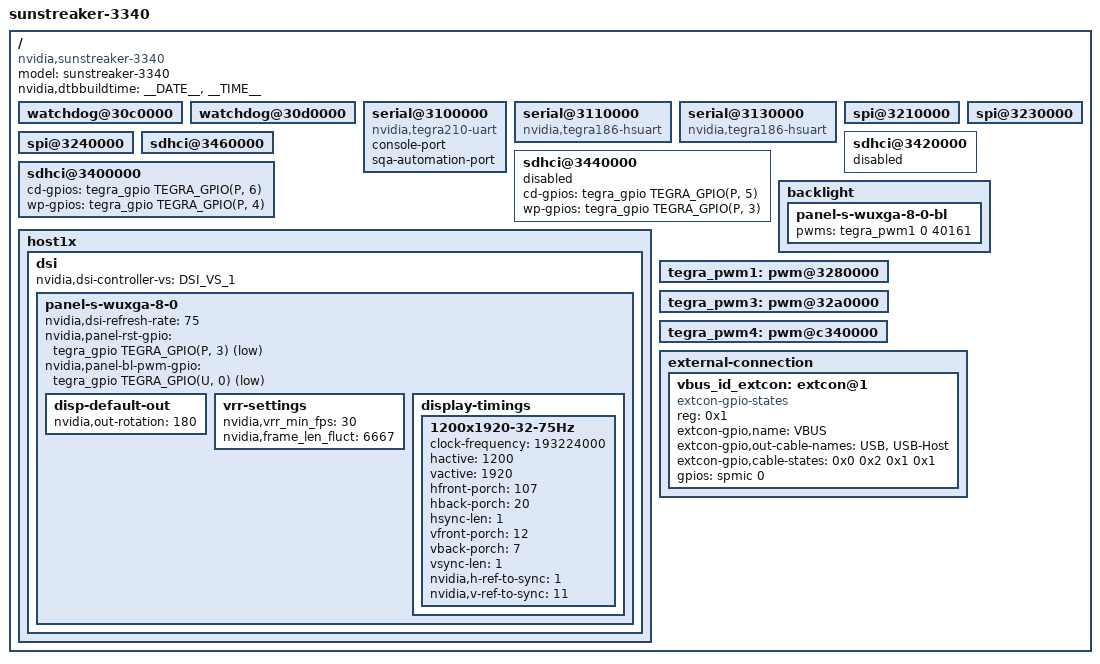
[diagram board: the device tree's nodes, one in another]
/*
 * tegra186-sunstreaker-common-e3340-0000-a00.dtsi: Sunstreaker common dtsi.
 *
 * Copyright (c) 2015, NVIDIA CORPORATION.  All rights reserved.
 *
 * This program is free software; you can redistribute it and/or modify
 * it under the terms of the GNU General Public License as published by
 * the Free Software Foundation; version 2 of the License.
 *
 * This program is distributed in the hope that it will be useful, but WITHOUT
 * ANY WARRANTY; without even the implied warranty of MERCHANTABILITY or
 * FITNESS FOR A PARTICULAR PURPOSE.  See the GNU General Public License for
 * more details.
 */

#include <dt-bindings/types.h>
#include <dt-bindings/gpio/tegra-gpio.h>
/dts-v1/;

/memreserve/ 0x80000000 0x00010000;

#include "tegra186-soc/tegra186-soc-vcm.dtsi"
#include "tegra186-cvm-simple-bus.dtsi"
#include "panel-s-wuxga-8-0.dtsi"
#include "tegra186-sunstreaker-slt-e3340-1099-a00-powermon.dtsi"
#include "tegra186-platforms/tegra186-sunstreaker-eqos.dtsi"
#include "tegra186-hdmi.dtsi"
#include "tegra186-dp.dtsi"

/ {
        model = "sunstreaker-3340";
        compatible = "nvidia,sunstreaker-3340", "nvidia,tegra186";

        nvidia,dtbbuildtime = __DATE__, __TIME__;
        #address-cells = <2>;
        #size-cells = <2>;

	watchdog@30c0000 {
		status = "okay";
	};

	watchdog@30d0000 {
		status = "okay";
	};

	serial@3100000 {
		compatible = "nvidia,tegra210-uart", "nvidia,tegra186-hsuart";
		console-port;
		sqa-automation-port;
		status = "okay";
	};

	serial@3110000 {
		compatible = "nvidia,tegra186-hsuart";
		status = "okay";
	};

	serial@3130000 {
		compatible = "nvidia,tegra186-hsuart";
		status = "okay";
	};

	spi@3210000 {
		status = "okay";
	};

	spi@3230000 {
		status = "okay";
	};

	spi@3240000 {
		status = "okay";
	};

	sdhci@3460000 {
		status = "okay";
	};

	sdhci@3440000 {
		cd-gpios = <&tegra_gpio TEGRA_GPIO(P, 5) 0>;
		wp-gpios = <&tegra_gpio TEGRA_GPIO(P, 3) 0>;
		status = "disabled";
	};

	sdhci@3420000 {
		status = "disabled";
	};

	sdhci@3400000 {
		cd-gpios = <&tegra_gpio TEGRA_GPIO(P, 6) 0>;
		wp-gpios = <&tegra_gpio TEGRA_GPIO(P, 4) 0>;
		status = "okay";
	};

	host1x {
		dsi {	/* dsi@15300000 */
			nvidia,dsi-controller-vs = <DSI_VS_1>;
			status = "okay";
			panel-s-wuxga-8-0 {
				nvidia,dsi-refresh-rate = <75>;
				nvidia,panel-rst-gpio = <&tegra_gpio TEGRA_GPIO(P, 3) 1>;
				nvidia,panel-bl-pwm-gpio = <&tegra_gpio TEGRA_GPIO(U, 0) 1>;
				disp-default-out {
					nvidia,out-rotation = <180>;
				};
				vrr-settings {
					nvidia,vrr_min_fps = <30>;
					nvidia,frame_len_fluct = <6667>;
				};
				display-timings {
					1200x1920-32-75Hz {
						clock-frequency = <193224000>;
						hactive = <1200>;
						vactive = <1920>;
						hfront-porch = <107>;
						hback-porch = <20>;
						hsync-len = <1>;
						vfront-porch = <12>;
						vback-porch = <7>;
						vsync-len = <1>;
						nvidia,h-ref-to-sync = <1>;
						nvidia,v-ref-to-sync = <11>;
					};
				};
			};
		};
	};

	backlight {
		panel-s-wuxga-8-0-bl {
			pwms = <&tegra_pwm1 0 40161>;
		};
	};

	tegra_pwm1: pwm@3280000 {
		status = "okay";
	};

	tegra_pwm3: pwm@32a0000 {
		status = "okay";
	};

	tegra_pwm4: pwm@c340000 {
		status = "okay";
	};

	external-connection {
		vbus_id_extcon: extcon@1 {
			compatible = "extcon-gpio-states";
			reg = <0x1>;
			extcon-gpio,name = "VBUS";
			extcon-gpio,out-cable-names = "USB", "USB-Host";
			extcon-gpio,cable-states = <0x0 0x2
						    0x1 0x1>;
			gpios = <&spmic 0 0>;
			#extcon-cells = <1>;
		};
	};
};

